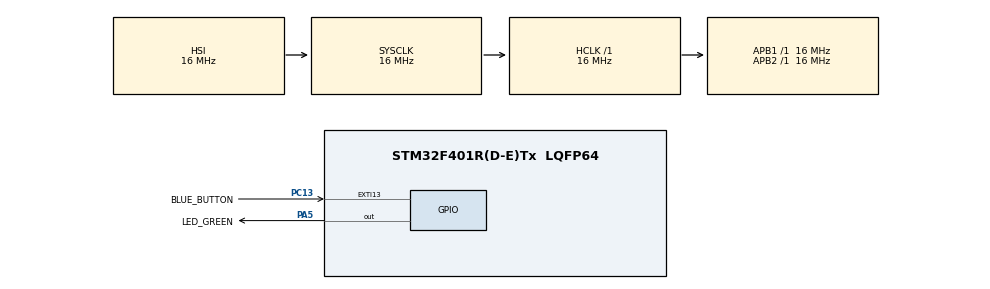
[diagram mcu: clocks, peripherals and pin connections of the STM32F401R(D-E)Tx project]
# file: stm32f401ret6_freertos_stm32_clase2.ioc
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FREERTOS.Tasks01=defaultTask,24,128,StartDefaultTask,Default,NULL,Dynamic,NULL,NULL;myTask02,24,128,StartTask02,Default,NULL,Dynamic,NULL,NULL
Mcu.Family=STM32F4
Mcu.Name=STM32F401R(D-E)Tx
Mcu.Package=LQFP64
NVIC.EXTI15_10_IRQn=true\:5\:0\:false\:false\:true\:true\:true\:true\:true
NVIC.PriorityGroup=NVIC_PRIORITYGROUP_4
NVIC.TIM1_UP_TIM10_IRQn=true\:15\:0\:false\:false\:true\:false\:false\:true\:true
NVIC.TimeBase=TIM1_UP_TIM10_IRQn
NVIC.TimeBaseIP=TIM10
PA13.Mode=Trace_Asynchronous_SW
PA13.Signal=SYS_JTMS-SWDIO
PA14.Mode=Trace_Asynchronous_SW
PA14.Signal=SYS_JTCK-SWCLK
PA5.GPIO_Label=LED_GREEN
PA5.Signal=GPIO_Output
PB3.Mode=Trace_Asynchronous_SW
PB3.Signal=SYS_JTDO-SWO
PC13-ANTI_TAMP.GPIO_Label=BLUE_BUTTON
PC13-ANTI_TAMP.Signal=GPXTI13
ProjectManager.HeapSize=0x200
ProjectManager.StackSize=0x400
ProjectManager.TargetToolchain=STM32CubeIDE
RCC.AHBFreq_Value=16000000
RCC.APB1Freq_Value=16000000
RCC.APB2Freq_Value=16000000
RCC.CortexFreq_Value=16000000
RCC.HSE_VALUE=25000000
RCC.HSI_VALUE=16000000
RCC.LSE_VALUE=32768
RCC.SYSCLKFreq_VALUE=16000000
RCC.VCOOutputFreq_Value=192000000
VP_FREERTOS_VS_CMSIS_V2.Mode=CMSIS_V2
VP_SYS_VS_tim10.Mode=TIM10
board=custom

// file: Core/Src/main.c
/* USER CODE BEGIN Header */
/**
  ******************************************************************************
  * @file           : main.c
  * @brief          : Main program body
  ******************************************************************************
  * @attention
  *
  * Copyright (c) 2025 STMicroelectronics.
  * All rights reserved.
  *
  * This software is licensed under terms that can be found in the LICENSE file
  * in the root directory of this software component.
  * If no LICENSE file comes with this software, it is provided AS-IS.
  *
  ******************************************************************************
  */
/* USER CODE END Header */
#include "main.h"
#include "cmsis_os.h"

/* Definitions for defaultTask */
osThreadId_t defaultTaskHandle;
const osThreadAttr_t defaultTask_attributes = {
  .name = "defaultTask",
  .stack_size = 128 * 4,
  .priority = (osPriority_t) osPriorityNormal,
};
/* Definitions for myTask02 */
osThreadId_t myTask02Handle;
const osThreadAttr_t myTask02_attributes = {
  .name = "myTask02",
  .stack_size = 128 * 4,
  .priority = (osPriority_t) osPriorityNormal,
};

void SystemClock_Config(void);
static void MX_GPIO_Init(void);
void StartDefaultTask(void *argument);
void StartTask02(void *argument);

/* USER CODE BEGIN PFP */
void Task_action(char message);
/* USER CODE END PFP */

int main(void)
{

  /* MCU Configuration--------------------------------------------------------*/

  /* Reset of all peripherals, Initializes the Flash interface and the Systick. */
  HAL_Init();

  /* Configure the system clock */
  SystemClock_Config();

  /* Initialize all configured peripherals */
  MX_GPIO_Init();

  /* Init scheduler */
  osKernelInitialize();

  /* Create the thread(s) */
  /* creation of defaultTask */
  defaultTaskHandle = osThreadNew(StartDefaultTask, NULL, &defaultTask_attributes);

  /* creation of myTask02 */
  myTask02Handle = osThreadNew(StartTask02, NULL, &myTask02_attributes);

  /* Start scheduler */
  osKernelStart();

  /* We should never get here as control is now taken by the scheduler */

  /* Infinite loop */
  while (1)
  {

  }
}

void SystemClock_Config(void)
{
  RCC_OscInitTypeDef RCC_OscInitStruct = {0};
  RCC_ClkInitTypeDef RCC_ClkInitStruct = {0};

  /** Configure the main internal regulator output voltage
  */
  __HAL_RCC_PWR_CLK_ENABLE();
  __HAL_PWR_VOLTAGESCALING_CONFIG(PWR_REGULATOR_VOLTAGE_SCALE2);

  /** Initializes the RCC Oscillators according to the specified parameters
  * in the RCC_OscInitTypeDef structure.
  */
  RCC_OscInitStruct.OscillatorType = RCC_OSCILLATORTYPE_HSI;
  RCC_OscInitStruct.HSIState = RCC_HSI_ON;
  RCC_OscInitStruct.HSICalibrationValue = RCC_HSICALIBRATION_DEFAULT;
  RCC_OscInitStruct.PLL.PLLState = RCC_PLL_NONE;
  if (HAL_RCC_OscConfig(&RCC_OscInitStruct) != HAL_OK)
  {
    Error_Handler();
  }

  /** Initializes the CPU, AHB and APB buses clocks
  */
  RCC_ClkInitStruct.ClockType = RCC_CLOCKTYPE_HCLK|RCC_CLOCKTYPE_SYSCLK
                              |RCC_CLOCKTYPE_PCLK1|RCC_CLOCKTYPE_PCLK2;
  RCC_ClkInitStruct.SYSCLKSource = RCC_SYSCLKSOURCE_HSI;
  RCC_ClkInitStruct.AHBCLKDivider = RCC_SYSCLK_DIV1;
  RCC_ClkInitStruct.APB1CLKDivider = RCC_HCLK_DIV1;
  RCC_ClkInitStruct.APB2CLKDivider = RCC_HCLK_DIV1;

  if (HAL_RCC_ClockConfig(&RCC_ClkInitStruct, FLASH_LATENCY_0) != HAL_OK)
  {
    Error_Handler();
  }
}

static void MX_GPIO_Init(void)
{
  GPIO_InitTypeDef GPIO_InitStruct = {0};

  /* GPIO Ports Clock Enable */
  __HAL_RCC_GPIOC_CLK_ENABLE();
  __HAL_RCC_GPIOA_CLK_ENABLE();
  __HAL_RCC_GPIOB_CLK_ENABLE();

  /*Configure GPIO pin Output Level */
  HAL_GPIO_WritePin(LED_GREEN_GPIO_Port, LED_GREEN_Pin, GPIO_PIN_RESET);

  /*Configure GPIO pin : BLUE_BUTTON_Pin */
  GPIO_InitStruct.Pin = BLUE_BUTTON_Pin;
  GPIO_InitStruct.Mode = GPIO_MODE_IT_RISING;
  GPIO_InitStruct.Pull = GPIO_NOPULL;
  HAL_GPIO_Init(BLUE_BUTTON_GPIO_Port, &GPIO_InitStruct);

  /*Configure GPIO pin : LED_GREEN_Pin */
  GPIO_InitStruct.Pin = LED_GREEN_Pin;
  GPIO_InitStruct.Mode = GPIO_MODE_OUTPUT_PP;
  GPIO_InitStruct.Pull = GPIO_NOPULL;
  GPIO_InitStruct.Speed = GPIO_SPEED_FREQ_LOW;
  HAL_GPIO_Init(LED_GREEN_GPIO_Port, &GPIO_InitStruct);

  /* EXTI interrupt init*/
  HAL_NVIC_SetPriority(EXTI15_10_IRQn, 5, 0);
  HAL_NVIC_EnableIRQ(EXTI15_10_IRQn);

}

/* USER CODE BEGIN 4 */
void Task_action(char message)
{
	ITM_SendChar(message);
	ITM_SendChar('\n');
}
/* USER CODE END 4 */

void StartDefaultTask(void *argument)
{
  /* USER CODE BEGIN 5 */
  /* Infinite loop */
  for(;;)
  {
	Task_action('0');
	//HAL_GPIO_TogglePin(LED_GREEN_GPIO_Port, LED_GREEN_Pin);
    osDelay(500); //Blocked task and return after an specified time
  }
  /* USER CODE END 5 */
}

void StartTask02(void *argument)
{
  /* USER CODE BEGIN StartTask02 */
  /* Infinite loop */
  for(;;)
  {
	Task_action('2');
    osDelay(200);
  }
  /* USER CODE END StartTask02 */
}

void HAL_TIM_PeriodElapsedCallback(TIM_HandleTypeDef *htim)
{
  if (htim->Instance == TIM10) {
    HAL_IncTick();
  }
}

void Error_Handler(void)
{
  __disable_irq();
  while (1)
  {
  }
}
